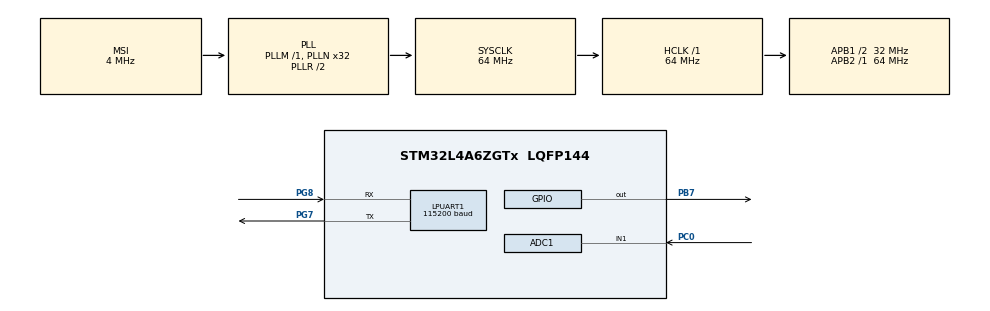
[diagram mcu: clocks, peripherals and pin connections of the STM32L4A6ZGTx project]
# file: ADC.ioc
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ADC1.Channel-0\#ChannelRegularConversion=ADC_CHANNEL_1
ADC1.NbrOfConversionFlag=1
ADC1.OffsetNumber-0\#ChannelRegularConversion=ADC_OFFSET_NONE
ADC1.Rank-0\#ChannelRegularConversion=1
ADC1.SamplingTime-0\#ChannelRegularConversion=ADC_SAMPLETIME_12CYCLES_5
ADC1.master=1
LPUART1.BaudRate=115200
LPUART1.WordLength=UART_WORDLENGTH_8B
Mcu.Family=STM32L4
Mcu.Name=STM32L4A6ZGTx
Mcu.Package=LQFP144
NVIC.PriorityGroup=NVIC_PRIORITYGROUP_4
PA13\ (JTMS/SWDIO).Mode=Serial_Wire
PA13\ (JTMS/SWDIO).Signal=SYS_JTMS-SWDIO
PA14\ (JTCK/SWCLK).Mode=Serial_Wire
PA14\ (JTCK/SWCLK).Signal=SYS_JTCK-SWCLK
PB7.PinState=GPIO_PIN_SET
PB7.Signal=GPIO_Output
PC0.Signal=ADCx_IN1
PG7.Mode=Asynchronous
PG7.Signal=LPUART1_TX
PG8.Mode=Asynchronous
PG8.Signal=LPUART1_RX
ProjectManager.HeapSize=0x200
ProjectManager.StackSize=0x400
ProjectManager.TargetToolchain=STM32CubeIDE
RCC.ADCFreq_Value=48000000
RCC.AHBFreq_Value=64000000
RCC.APB1CLKDivider=RCC_HCLK_DIV2
RCC.APB1Freq_Value=32000000
RCC.APB1TimFreq_Value=64000000
RCC.APB2Freq_Value=64000000
RCC.APB2TimFreq_Value=64000000
RCC.CortexFreq_Value=64000000
RCC.FLatency=FLASH_LATENCY_3
RCC.HCLKFreq_Value=64000000
RCC.HSE_VALUE=8000000
RCC.HSI48_VALUE=48000000
RCC.HSI_VALUE=16000000
RCC.MSI_VALUE=4000000
RCC.PLLN=32
RCC.PLLSAI1N=24
RCC.SYSCLKFreq_VALUE=64000000
RCC.SYSCLKSource=RCC_SYSCLKSOURCE_PLLCLK
RCC.USBFreq_Value=48000000
RCC.VCOOutputFreq_Value=128000000
SH.ADCx_IN1.0=ADC1_IN1,IN1-Single-Ended
board=NUCLEO-L4A6ZG

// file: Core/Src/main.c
#include "main.h"
#include <stdio.h>
#include <string.h>

ADC_HandleTypeDef hadc1;
UART_HandleTypeDef hlpuart1;

/* USER CODE BEGIN PV */
uint32_t adc_value = 0;
char msg[30];
/* USER CODE END PV */

float calculate_voltage(uint32_t adc_value) {
    return ((float)adc_value / 4096) * 3.3;
}

void SystemClock_Config(void);
void MX_GPIO_Init(void);
void MX_ADC1_Init(void);
void MX_LPUART1_UART_Init(void);

int main(void) {
    HAL_Init();
    SystemClock_Config();

    /* Initialize all configured peripherals */
    MX_GPIO_Init();
    MX_ADC1_Init();
    MX_LPUART1_UART_Init();

    while (1) {
        HAL_ADC_Start(&hadc1);
        HAL_ADC_PollForConversion(&hadc1, HAL_MAX_DELAY);
        adc_value = HAL_ADC_GetValue(&hadc1);
        sprintf(msg, "ADC: %lu   Voltage: %lf V\r\n", adc_value, calculate_voltage(adc_value));
        HAL_UART_Transmit(&hlpuart1, (uint8_t*)msg, strlen(msg), HAL_MAX_DELAY);
        HAL_Delay(1000);
        if (adc_value < 2000) {
            HAL_GPIO_WritePin(GPIOB, GPIO_PIN_7, GPIO_PIN_SET);
        } else {
            HAL_GPIO_WritePin(GPIOB, GPIO_PIN_7, GPIO_PIN_RESET);
        }
    }
}

void SystemClock_Config(void) {
    RCC_OscInitTypeDef RCC_OscInitStruct = {0};
    RCC_ClkInitTypeDef RCC_ClkInitStruct = {0};

    if (HAL_PWREx_ControlVoltageScaling(PWR_REGULATOR_VOLTAGE_SCALE1) != HAL_OK) {
        Error_Handler();
    }

    RCC_OscInitStruct.OscillatorType = RCC_OSCILLATORTYPE_MSI;
    RCC_OscInitStruct.MSIState = RCC_MSI_ON;
    RCC_OscInitStruct.MSICalibrationValue = 0;
    RCC_OscInitStruct.MSIClockRange = RCC_MSIRANGE_6;
    RCC_OscInitStruct.PLL.PLLState = RCC_PLL_ON;
    RCC_OscInitStruct.PLL.PLLSource = RCC_PLLSOURCE_MSI;
    RCC_OscInitStruct.PLL.PLLM = 1;
    RCC_OscInitStruct.PLL.PLLN = 32;
    RCC_OscInitStruct.PLL.PLLP = RCC_PLLP_DIV2;
    RCC_OscInitStruct.PLL.PLLQ = RCC_PLLQ_DIV2;
    RCC_OscInitStruct.PLL.PLLR = RCC_PLLR_DIV2;
    if (HAL_RCC_OscConfig(&RCC_OscInitStruct) != HAL_OK) {
        Error_Handler();
    }

    RCC_ClkInitStruct.ClockType = RCC_CLOCKTYPE_HCLK | RCC_CLOCKTYPE_SYSCLK
                                  | RCC_CLOCKTYPE_PCLK1 | RCC_CLOCKTYPE_PCLK2;
    RCC_ClkInitStruct.SYSCLKSource = RCC_SYSCLKSOURCE_PLLCLK;
    RCC_ClkInitStruct.AHBCLKDivider = RCC_SYSCLK_DIV1;
    RCC_ClkInitStruct.APB1CLKDivider = RCC_HCLK_DIV2;
    RCC_ClkInitStruct.APB2CLKDivider = RCC_HCLK_DIV1;

    if (HAL_RCC_ClockConfig(&RCC_ClkInitStruct, FLASH_LATENCY_3) != HAL_OK) {
        Error_Handler();
    }
}

void MX_ADC1_Init(void) {
    ADC_MultiModeTypeDef multimode = {0};
    ADC_ChannelConfTypeDef sConfig = {0};

    hadc1.Instance = ADC1;
    hadc1.Init.ClockPrescaler = ADC_CLOCK_ASYNC_DIV1;
    hadc1.Init.Resolution = ADC_RESOLUTION_12B;
    hadc1.Init.DataAlign = ADC_DATAALIGN_RIGHT;
    hadc1.Init.ScanConvMode = ADC_SCAN_DISABLE;
    hadc1.Init.EOCSelection = ADC_EOC_SINGLE_CONV;
    hadc1.Init.LowPowerAutoWait = DISABLE;
    hadc1.Init.ContinuousConvMode = DISABLE;
    hadc1.Init.NbrOfConversion = 1;
    hadc1.Init.DiscontinuousConvMode = DISABLE;
    hadc1.Init.ExternalTrigConv = ADC_SOFTWARE_START;
    hadc1.Init.ExternalTrigConvEdge = ADC_EXTERNALTRIGCONVEDGE_NONE;
    hadc1.Init.DMAContinuousRequests = DISABLE;
    hadc1.Init.Overrun = ADC_OVR_DATA_PRESERVED;
    hadc1.Init.OversamplingMode = DISABLE;
    if (HAL_ADC_Init(&hadc1) != HAL_OK) {
        Error_Handler();
    }

    /* Run the ADC calibration in single-ended mode */
    if (HAL_ADCEx_Calibration_Start(&hadc1, ADC_SINGLE_ENDED) != HAL_OK) {
        Error_Handler();
    }

    multimode.Mode = ADC_MODE_INDEPENDENT;
    if (HAL_ADCEx_MultiModeConfigChannel(&hadc1, &multimode) != HAL_OK) {
        Error_Handler();
    }

    sConfig.Channel = ADC_CHANNEL_1;
    sConfig.Rank = ADC_REGULAR_RANK_1;
    sConfig.SamplingTime = ADC_SAMPLETIME_12CYCLES_5;
    sConfig.SingleDiff = ADC_SINGLE_ENDED;
    sConfig.OffsetNumber = ADC_OFFSET_NONE;
    sConfig.Offset = 0;
    if (HAL_ADC_ConfigChannel(&hadc1, &sConfig) != HAL_OK) {
        Error_Handler();
    }
}

void MX_LPUART1_UART_Init(void) {
    hlpuart1.Instance = LPUART1;
    hlpuart1.Init.BaudRate = 115200;
    hlpuart1.Init.WordLength = UART_WORDLENGTH_8B;
    hlpuart1.Init.StopBits = UART_STOPBITS_1;
    hlpuart1.Init.Parity = UART_PARITY_NONE;
    hlpuart1.Init.Mode = UART_MODE_TX_RX;
    hlpuart1.Init.HwFlowCtl = UART_HWCONTROL_NONE;
    hlpuart1.Init.OneBitSampling = UART_ONE_BIT_SAMPLE_DISABLE;
    hlpuart1.AdvancedInit.AdvFeatureInit = UART_ADVFEATURE_NO_INIT;
    if (HAL_UART_Init(&hlpuart1) != HAL_OK) {
        Error_Handler();
    }
}

void MX_GPIO_Init(void) {
    GPIO_InitTypeDef GPIO_InitStruct = {0};
    __HAL_RCC_GPIOC_CLK_ENABLE();
    __HAL_RCC_GPIOG_CLK_ENABLE();
    HAL_PWREx_EnableVddIO2();
    __HAL_RCC_GPIOA_CLK_ENABLE();
    __HAL_RCC_GPIOB_CLK_ENABLE();

    HAL_GPIO_WritePin(GPIOB, GPIO_PIN_7, GPIO_PIN_SET);

    GPIO_InitStruct.Pin = GPIO_PIN_7;
    GPIO_InitStruct.Mode = GPIO_MODE_OUTPUT_PP;
    GPIO_InitStruct.Pull = GPIO_NOPULL;
    GPIO_InitStruct.Speed = GPIO_SPEED_FREQ_LOW;
    HAL_GPIO_Init(GPIOB, &GPIO_InitStruct);
}

void Error_Handler(void) {
    __disable_irq();
    while (1) {
    }
}
